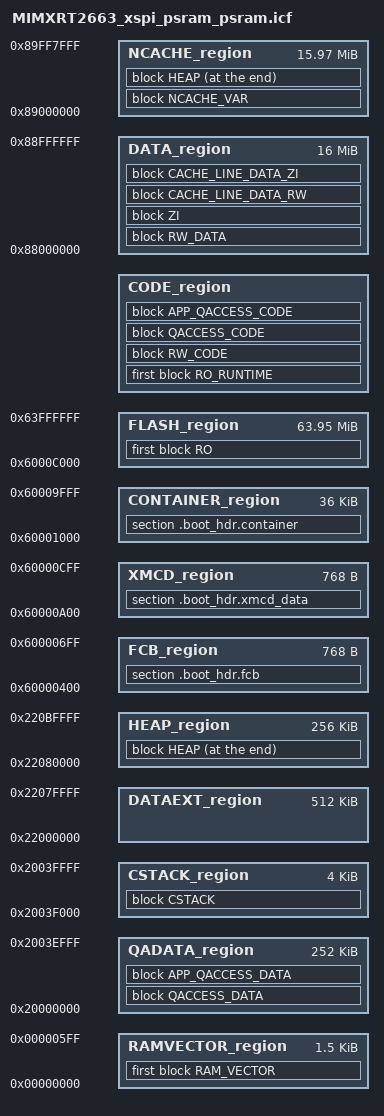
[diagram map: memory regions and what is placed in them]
/*
** ###################################################################
**     Processors:          MIMXRT2663AHP8A
**                          MIMXRT2663CHPAA
**                          MIMXRT2663CVVAA
**                          MIMXRT2663DHPAA
**                          MIMXRT2663DVVAA
**                          MIMXRT2663XHP8A
**                          MIMXRT2663XVV8A
**
**     Compiler:            IAR ANSI C/C++ Compiler for ARM
**     Reference manual:    iMXRT2660RM Rev.2 DraftA, 05/2024
**     Version:             rev. 1.0, 2024-11-05
**     Build:               b260603
**
**     Abstract:
**         Linker file for the IAR ANSI C/C++ Compiler for ARM
**
**     Copyright 1997-2016 Freescale Semiconductor, Inc.
**     Copyright 2016-2026 NXP
**     SPDX-License-Identifier: BSD-3-Clause
**
**     http:                 www.nxp.com
**     mail:                 support@nxp.com
**
** ###################################################################
*/

/*
 * Example-private copy for xspi_psram_polling_transfer (target: psram, see
 * reconfig.cmake). Based on
 * devices/RT/RT2660/MIMXRT2663/iar/MIMXRT2663xxxxx_psram.icf:
 *  - carves a 32 KB linker-untouched test window (__PSRAM_TEST_START__) out
 *    of the NCACHE tail;
 *  - pins the XSPI/LLC drivers, the board ops and hardware_init into
 *    ITCM/DTCM so the XSPI1 controller can be re-programmed while the
 *    image lives behind it.
 */

/* ========================== Hardware addresses ========================== */
/* ======================================================================== */
define symbol m_flash_start       = 0x60000000;
define symbol m_flash_size        = 0x04000000;
define symbol m_itcm_start        = 0x00000000;
define symbol m_itcm_size         = 0x00040000;
define symbol m_dtcm_start        = 0x20000000;
define symbol m_dtcm_size         = 0x00040000;
define symbol m_sram0_start       = 0x22000000;
define symbol m_sram0_size        = 0x00040000;
define symbol m_sram1_start       = 0x22040000;
define symbol m_sram1_size        = 0x00040000;
define symbol m_sram2_start       = 0x22080000;
define symbol m_sram2_size        = 0x00040000;
define symbol m_psram_start       = 0x88000000;
define symbol m_psram_size        = 0x02000000;

/* ========================== Offsets and sizes =========================== */
/* ======================================================================== */
define symbol m_fcb_offset        = 0x400;
define symbol m_fcb_size          = 0x300;
define symbol m_xmcd_offset       = 0xA00;
define symbol m_xmcd_size         = 0x300;
define symbol m_container_offset  = 0x1000;
define symbol m_container_size    = 0x9000;
define symbol m_vector_table_size = 0x600;
define symbol m_app_image_offset  = 0xC000;
define symbol m_ncache_size       = 0x01000000;  /* PSRAM last 16M reserved for NCACHE */

/* ====================== Region start/end addresses ====================== */
/* ======================================================================== */
define symbol m_fcb_start         = m_flash_start + m_fcb_offset;
define symbol m_fcb_end           = m_fcb_start + m_fcb_size - 1;
define symbol m_xmcd_start        = m_flash_start + m_xmcd_offset;
define symbol m_xmcd_end          = m_xmcd_start + m_xmcd_size - 1;
define symbol m_container_start   = m_flash_start + m_container_offset;
define symbol m_container_end     = m_container_start + m_container_size - 1;
define symbol m_text_start        = m_flash_start + m_app_image_offset;
define symbol m_text_end          = m_flash_start + m_flash_size - 1;
define symbol m_ncache_start      = m_psram_start + m_psram_size - m_ncache_size;
define symbol m_psram_test_size   = 0x8000;  /* linker-untouched example test window */
define symbol m_psram_test_start  = m_psram_start + m_psram_size - m_psram_test_size;
define symbol m_ncache_end        = m_psram_test_start - 1;
define symbol m_heap_start        = m_sram2_start;
define symbol m_heap_end          = m_sram2_start + m_sram2_size - 1;
define symbol m_dataext_start     = m_sram0_start;
define symbol m_dataext_end       = m_sram1_start + m_sram1_size - 1;

if (isdefinedsymbol(__ram_vector_table__)) {
  define symbol m_ramvector_start = m_itcm_start;
  define symbol m_ramvector_end   = m_itcm_start + m_vector_table_size - 1;
}

if (isdefinedsymbol(__stack_size__)) {
  define symbol __size_cstack__ = __stack_size__;
} else {
  define symbol __size_cstack__ = 0x1000;
}

if (isdefinedsymbol(__heap_size__)) {
  define symbol __size_heap__ = __heap_size__;
} else {
  define symbol __size_heap__ = 0x1000;
}

define symbol m_rvt_offset        = isdefinedsymbol(__ram_vector_table__) ? m_vector_table_size : 0;

define symbol m_qacode_start      = m_itcm_start + m_rvt_offset;
define symbol m_qacode_end        = m_itcm_start + m_itcm_size - 1;
define symbol m_qadata_start      = m_dtcm_start;
define symbol m_qadata_end        = m_dtcm_start + m_dtcm_size - __size_cstack__ - 1;
define symbol m_cstack_start      = m_dtcm_start + m_dtcm_size - __size_cstack__;
define symbol m_cstack_end        = m_dtcm_start + m_dtcm_size - 1;

/* ================ Target specific CODE / DATA addresses ================= */
/* ======================================================================== */
define symbol m_code_start        = m_itcm_start + m_rvt_offset;
define symbol m_code_end          = m_itcm_start + m_itcm_size - 1;
define symbol m_data_start        = m_psram_start;
define symbol m_data_end          = m_psram_start + m_psram_size - m_ncache_size - 1;  /* PSRAM first 16M */

/* ============================ Memory regions ============================ */
/* ======================================================================== */
define memory mem with size = 4G;
define region FCB_region       = mem:[from m_fcb_start       to m_fcb_end];
define region XMCD_region      = mem:[from m_xmcd_start      to m_xmcd_end];
define region CONTAINER_region = mem:[from m_container_start to m_container_end];
define region FLASH_region     = mem:[from m_text_start      to m_text_end];
/* CODE_region == QACODE_region here (both ITCM). ILINK accepts overlapping
 * regions; do NOT add `place in QACODE_region {}` -- code placed via
 * `place in CODE_region {}` already occupies the range. */
define region CODE_region      = mem:[from m_code_start      to m_code_end];
define region DATA_region      = mem:[from m_data_start      to m_data_end];
define region CSTACK_region    = mem:[from m_cstack_start    to m_cstack_end];
define region QACODE_region    = mem:[from m_qacode_start    to m_qacode_end];
define region QADATA_region    = mem:[from m_qadata_start    to m_qadata_end];
define region NCACHE_region    = mem:[from m_ncache_start    to m_ncache_end];
define region HEAP_region      = mem:[from m_heap_start      to m_heap_end];
define region DATAEXT_region   = mem:[from m_dataext_start   to m_dataext_end];

if (isdefinedsymbol(__ram_vector_table__)) {
  define region RAMVECTOR_region = mem:[from m_ramvector_start to m_ramvector_end];
}

/* ========================== Block definitions =========================== */
/* ======================================================================== */
define block RO                  with fixed order { readonly section .intvec, readonly };
define block RO_RUNTIME          { rw code, rw section .rodata* };
define block RW_CODE             { section .textrw };
define block RW_DATA             { rw data };
define block ZI                  { zi };
define block QACCESS_CODE        { section CodeQuickAccess };
define block QACCESS_DATA        { section DataQuickAccess };
define block NCACHE_VAR          { section NonCacheable, section NonCacheable.init };
define block CACHE_LINE_DATA_RW  with alignment = 32, end alignment = 32 { section CacheLineData.init };
define block CACHE_LINE_DATA_ZI  with alignment = 32, end alignment = 32 { section CacheLineData };
define block CSTACK              with alignment = 8, size = __size_cstack__ { };
define block HEAP                with alignment = 8, size = __size_heap__   { };

if (isdefinedsymbol(__ram_vector_table__)) {
  define block RAM_VECTOR with size = m_vector_table_size { };
  keep { block RAM_VECTOR };
}

define block APP_QACCESS_CODE {
  ro code object "fsl_xspi*",
  ro code object "fsl_llc*",
  ro code object "xspi_psram_ops*",
  ro code object "hardware_init*",
  rw code object "fsl_xspi*",
  rw code object "fsl_llc*",
  rw code object "xspi_psram_ops*",
  rw code object "hardware_init*",
  section .textrw object "fsl_xspi*",
  section .textrw object "fsl_llc*",
  section .textrw object "xspi_psram_ops*",
  section .textrw object "hardware_init*"
};

define block APP_QACCESS_DATA {
  ro data object "fsl_xspi*",
  ro data object "fsl_llc*",
  ro data object "xspi_psram_ops*",
  ro data object "hardware_init*",
  rw data section .data* object "fsl_xspi*",
  rw data section .data* object "fsl_llc*",
  rw data section .data* object "xspi_psram_ops*",
  rw data section .data* object "hardware_init*",
  rw data section .rodata* object "fsl_xspi*",
  rw data section .rodata* object "fsl_llc*",
  rw data section .rodata* object "xspi_psram_ops*",
  rw data section .rodata* object "hardware_init*",
  zi object "fsl_xspi*",
  zi object "fsl_llc*",
  zi object "xspi_psram_ops*",
  zi object "hardware_init*"
};

/* ====================== Initialization directives ======================= */
/* ======================================================================== */
initialize by copy {
  readwrite,
  section .textrw,
  section CacheLineData.init,
  section DataQuickAccess,
  section CodeQuickAccess
};

/* Readonly (code + .rodata) is scatter-copied from Flash (LMA) to
 * the CODE_region VMA at startup, then executes from RAM. `packing = none`
 * keeps LMA byte-identical to VMA. `except {}` leaves .intvec (ROM
 * entrypoint) and boot headers (ROM reads them before scatter) in Flash. */
initialize by copy with packing = none { readonly }
  except {
    readonly section .intvec,
    section .boot_hdr.fcb,
    section .boot_hdr.xmcd_data,
    section .boot_hdr.container
  };

do not initialize { section .noinit };
keep { section .boot_hdr.fcb, section .boot_hdr.xmcd_data, section .boot_hdr.container };

/* ========================= Placement directives ========================= */
/* ======================================================================== */
place in FCB_region       { section .boot_hdr.fcb };
place in XMCD_region      { section .boot_hdr.xmcd_data };
place in CONTAINER_region { section .boot_hdr.container };
place in FLASH_region     { first block RO };

if (isdefinedsymbol(__ram_vector_table__)) {
  place in RAMVECTOR_region    { first block RAM_VECTOR };
}

place in CODE_region      { first block RO_RUNTIME };
place in CODE_region      { block RW_CODE };
place in CODE_region      { block QACCESS_CODE };
place in CODE_region      { block APP_QACCESS_CODE };

place in QADATA_region    { block QACCESS_DATA };
place in QADATA_region    { block APP_QACCESS_DATA };
place in DATA_region      { block RW_DATA };
place in DATA_region      { block ZI };
place in DATA_region      { block CACHE_LINE_DATA_RW, block CACHE_LINE_DATA_ZI };

place in CSTACK_region    { block CSTACK };
place in NCACHE_region    { block NCACHE_VAR };
place in DATAEXT_region   { };

if (isdefinedsymbol(__heap_noncacheable__)) {
  place at end of NCACHE_region { block HEAP };
} else {
  place at end of HEAP_region   { block HEAP };
}

/* =========================== Exported symbols =========================== */
/* ======================================================================== */
define exported symbol __VECTOR_TABLE             = m_text_start;
if (isdefinedsymbol(__ram_vector_table__)) {
  define exported symbol __VECTOR_RAM             = m_ramvector_start;
} else {
  define exported symbol __VECTOR_RAM             = m_text_start;
}
define exported symbol __RAM_VECTOR_TABLE_SIZE    = m_rvt_offset;
define exported symbol __NCACHE_REGION_START      = m_ncache_start;
define exported symbol __NCACHE_REGION_SIZE       = m_ncache_end - m_ncache_start + 1;
define exported symbol __CONTAINER_IMG_OFFSET     = m_app_image_offset - m_container_offset;
define exported symbol __CONTAINER_IMG_LOAD_ADDR  = m_text_start;
define exported symbol __CONTAINER_IMG_ENTRY_ADDR = m_text_start;
define exported symbol __PSRAM_TEST_START__       = m_psram_test_start;
define exported symbol __PSRAM_TEST_SIZE__        = m_psram_test_size;
